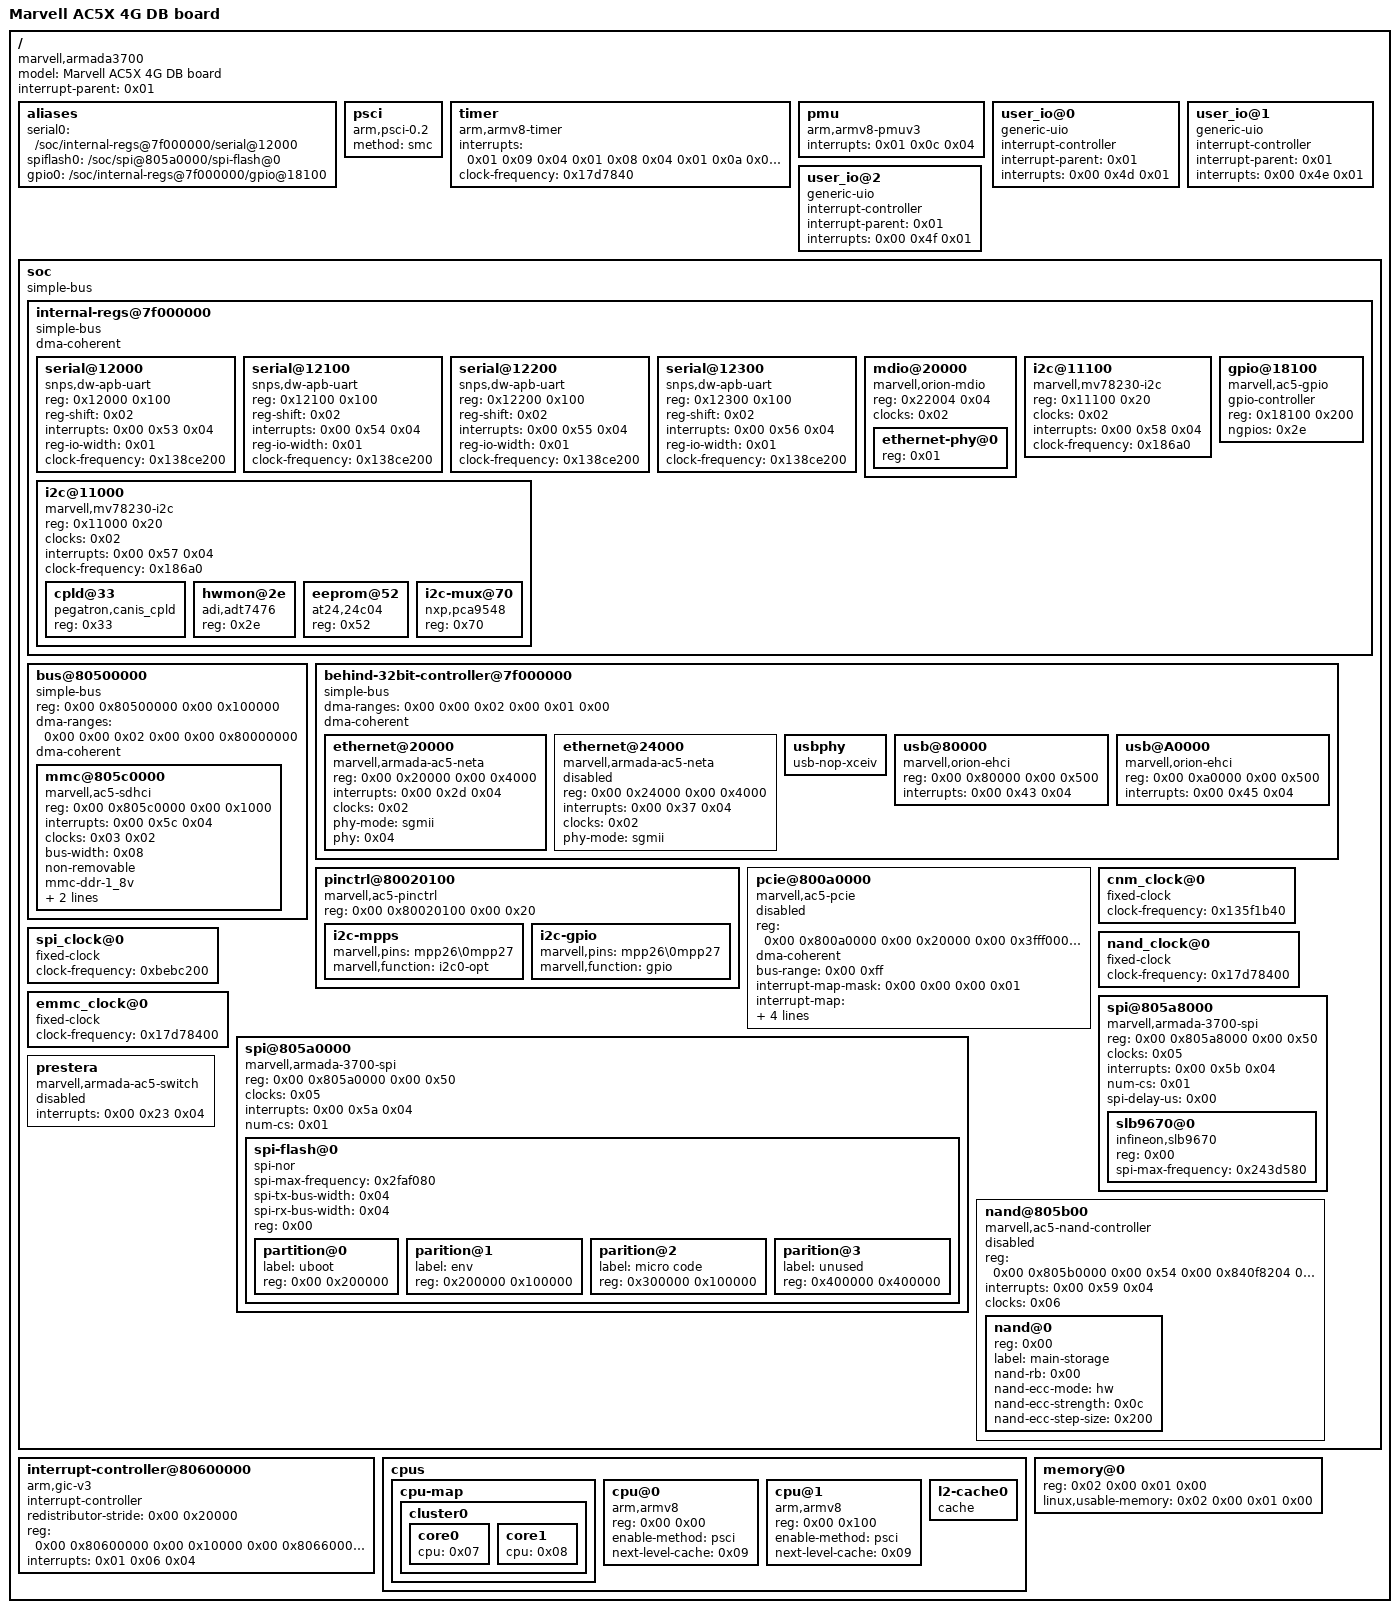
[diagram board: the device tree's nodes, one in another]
/dts-v1/;

/ {
	model = "Marvell AC5X 4G DB board";
	compatible = "marvell,armada3700";
	interrupt-parent = <0x01>;
	#address-cells = <0x02>;
	#size-cells = <0x02>;

	aliases {
		serial0 = "/soc/internal-regs@7f000000/serial@12000";
		spiflash0 = "/soc/spi@805a0000/spi-flash@0";
		gpio0 = "/soc/internal-regs@7f000000/gpio@18100";
	};

	psci {
		compatible = "arm,psci-0.2";
		method = "smc";
	};

	timer {
		compatible = "arm,armv8-timer";
		interrupts = <0x01 0x09 0x04 0x01 0x08 0x04 0x01 0x0a 0x04 0x01 0x07 0x04>;
		clock-frequency = <0x17d7840>;
	};

	pmu {
		compatible = "arm,armv8-pmuv3";
		interrupts = <0x01 0x0c 0x04>;
	};

	user_io@0 {
		compatible = "generic-uio";
		status = "okay";
		interrupt-controller;
		interrupt-parent = <0x01>;
		interrupts = <0x00 0x4d 0x01>;
	};

	user_io@1 {
		compatible = "generic-uio";
		status = "okay";
		interrupt-controller;
		interrupt-parent = <0x01>;
		interrupts = <0x00 0x4e 0x01>;
	};

	user_io@2 {
		compatible = "generic-uio";
		status = "okay";
		interrupt-controller;
		interrupt-parent = <0x01>;
		interrupts = <0x00 0x4f 0x01>;
	};

	soc {
		compatible = "simple-bus";
		#address-cells = <0x02>;
		#size-cells = <0x02>;
		ranges;

		internal-regs@7f000000 {
			#address-cells = <0x01>;
			#size-cells = <0x01>;
			compatible = "simple-bus";
			ranges = <0x00 0x00 0x7f000000 0x1000000>;
			dma-coherent;

			serial@12000 {
				compatible = "snps,dw-apb-uart";
				reg = <0x12000 0x100>;
				reg-shift = <0x02>;
				interrupts = <0x00 0x53 0x04>;
				reg-io-width = <0x01>;
				clock-frequency = <0x138ce200>;
				status = "okay";
			};

			serial@12100 {
				compatible = "snps,dw-apb-uart";
				reg = <0x12100 0x100>;
				reg-shift = <0x02>;
				interrupts = <0x00 0x54 0x04>;
				reg-io-width = <0x01>;
				clock-frequency = <0x138ce200>;
				status = "okay";
			};

			serial@12200 {
				compatible = "snps,dw-apb-uart";
				reg = <0x12200 0x100>;
				reg-shift = <0x02>;
				interrupts = <0x00 0x55 0x04>;
				reg-io-width = <0x01>;
				clock-frequency = <0x138ce200>;
				status = "okay";
			};

			serial@12300 {
				compatible = "snps,dw-apb-uart";
				reg = <0x12300 0x100>;
				reg-shift = <0x02>;
				interrupts = <0x00 0x56 0x04>;
				reg-io-width = <0x01>;
				clock-frequency = <0x138ce200>;
				status = "okay";
			};

			mdio@20000 {
				#address-cells = <0x01>;
				#size-cells = <0x00>;
				compatible = "marvell,orion-mdio";
				reg = <0x22004 0x04>;
				clocks = <0x02>;
				status = "okay";

				ethernet-phy@0 {
					reg = <0x01>;
					phandle = <0x04>;
				};
			};

			i2c@11000 {
				compatible = "marvell,mv78230-i2c";
				reg = <0x11000 0x20>;
				clocks = <0x02>;
				clock-names = "core";
				interrupts = <0x00 0x57 0x04>;
				clock-frequency = <0x186a0>;
				status = "okay";
				#address-cells = <0x01>;
				#size-cells = <0x00>;

				cpld@33 {
					compatible = "pegatron,canis_cpld";
					reg = <0x33>;
				};

				hwmon@2e {
					compatible = "adi,adt7476";
					reg = <0x2e>;
				};

				eeprom@52 {
					compatible = "at24,24c04";
					reg = <0x52>;
				};

				i2c-mux@70 {
					compatible = "nxp,pca9548";
					#address-cells = <0x01>;
					#size-cells = <0x00>;
					reg = <0x70>;
				};
			};

			i2c@11100 {
				compatible = "marvell,mv78230-i2c";
				reg = <0x11100 0x20>;
				clocks = <0x02>;
				clock-names = "core";
				interrupts = <0x00 0x58 0x04>;
				clock-frequency = <0x186a0>;
				status = "okay";
				#address-cells = <0x01>;
				#size-cells = <0x00>;
			};

			gpio@18100 {
				compatible = "marvell,ac5-gpio";
				#gpio-cells = <0x02>;
				gpio-controller;
				reg = <0x18100 0x200>;
				ngpios = <0x2e>;
				status = "okay";
			};
		};

		bus@80500000 {
			compatible = "simple-bus";
			ranges;
			#address-cells = <0x02>;
			#size-cells = <0x02>;
			reg = <0x00 0x80500000 0x00 0x100000>;
			dma-ranges = <0x00 0x00 0x02 0x00 0x00 0x80000000>;
			dma-coherent;

			mmc@805c0000 {
				compatible = "marvell,ac5-sdhci\0marvell,armada-ap806-sdhci";
				reg = <0x00 0x805c0000 0x00 0x1000>;
				interrupts = <0x00 0x5c 0x04>;
				clocks = <0x03 0x02>;
				clock-names = "core\0axi";
				bus-width = <0x08>;
				non-removable;
				mmc-ddr-1_8v;
				mmc-hs200-1_8v;
				mmc-hs400-1_8v;
			};
		};

		behind-32bit-controller@7f000000 {
			compatible = "simple-bus";
			#address-cells = <0x02>;
			#size-cells = <0x02>;
			ranges = <0x00 0x00 0x00 0x7f000000 0x00 0x1000000>;
			dma-ranges = <0x00 0x00 0x02 0x00 0x01 0x00>;
			dma-coherent;

			ethernet@20000 {
				compatible = "marvell,armada-ac5-neta";
				reg = <0x00 0x20000 0x00 0x4000>;
				interrupts = <0x00 0x2d 0x04>;
				clocks = <0x02>;
				status = "okay";
				phy-mode = "sgmii";
				phy = <0x04>;
			};

			ethernet@24000 {
				compatible = "marvell,armada-ac5-neta";
				reg = <0x00 0x24000 0x00 0x4000>;
				interrupts = <0x00 0x37 0x04>;
				clocks = <0x02>;
				status = "disabled";
				phy-mode = "sgmii";
			};

			usbphy {
				compatible = "usb-nop-xceiv";
				#phy-cells = <0x00>;
			};

			usb@80000 {
				compatible = "marvell,orion-ehci";
				reg = <0x00 0x80000 0x00 0x500>;
				interrupts = <0x00 0x43 0x04>;
				status = "okay";
			};

			usb@A0000 {
				reg = <0x00 0xa0000 0x00 0x500>;
				interrupts = <0x00 0x45 0x04>;
				status = "okay";
				compatible = "marvell,orion-ehci";
			};
		};

		pinctrl@80020100 {
			compatible = "marvell,ac5-pinctrl\0syscon\0simple-mfd";
			reg = <0x00 0x80020100 0x00 0x20>;

			i2c-mpps {
				marvell,pins = "mpp26\0mpp27";
				marvell,function = "i2c0-opt";
			};

			i2c-gpio {
				marvell,pins = "mpp26\0mpp27";
				marvell,function = "gpio";
			};
		};

		pcie@800a0000 {
			compatible = "marvell,ac5-pcie\0snps,dw-pcie";
			reg = <0x00 0x800a0000 0x00 0x20000 0x00 0x3fff0000 0x00 0x10000>;
			reg-names = "ctrl\0config";
			#address-cells = <0x03>;
			#size-cells = <0x02>;
			#interrupt-cells = <0x01>;
			device_type = "pci";
			dma-coherent;
			bus-range = <0x00 0xff>;
			ranges = <0x82000000 0x00 0x30000000 0x00 0x30000000 0x00 0xfff0000>;
			interrupt-map-mask = <0x00 0x00 0x00 0x01>;
			interrupt-map = <0x00 0x00 0x00 0x01 0x01 0x00 0x63 0x04>;
			interrupts = <0x00 0x63 0x04>;
			num-lanes = <0x01>;
			status = "disabled";
			clocks = <0x02>;
		};

		cnm_clock@0 {
			compatible = "fixed-clock";
			#clock-cells = <0x00>;
			clock-frequency = <0x135f1b40>;
			phandle = <0x02>;
		};

		spi_clock@0 {
			compatible = "fixed-clock";
			#clock-cells = <0x00>;
			clock-frequency = <0xbebc200>;
			phandle = <0x05>;
		};

		nand_clock@0 {
			compatible = "fixed-clock";
			#clock-cells = <0x00>;
			clock-frequency = <0x17d78400>;
			phandle = <0x06>;
		};

		emmc_clock@0 {
			compatible = "fixed-clock";
			#clock-cells = <0x00>;
			clock-frequency = <0x17d78400>;
			phandle = <0x03>;
		};

		spi@805a0000 {
			compatible = "marvell,armada-3700-spi";
			reg = <0x00 0x805a0000 0x00 0x50>;
			#address-cells = <0x01>;
			#size-cells = <0x00>;
			clocks = <0x05>;
			interrupts = <0x00 0x5a 0x04>;
			num-cs = <0x01>;
			status = "okay";

			spi-flash@0 {
				compatible = "spi-nor";
				spi-max-frequency = <0x2faf080>;
				spi-tx-bus-width = <0x04>;
				spi-rx-bus-width = <0x04>;
				reg = <0x00>;
				#address-cells = <0x01>;
				#size-cells = <0x01>;

				partition@0 {
					label = "uboot";
					reg = <0x00 0x200000>;
				};

				parition@1 {
					label = "env";
					reg = <0x200000 0x100000>;
				};

				parition@2 {
					label = "micro code";
					reg = <0x300000 0x100000>;
				};

				parition@3 {
					label = "unused";
					reg = <0x400000 0x400000>;
				};
			};
		};

		spi@805a8000 {
			compatible = "marvell,armada-3700-spi";
			reg = <0x00 0x805a8000 0x00 0x50>;
			#address-cells = <0x01>;
			#size-cells = <0x00>;
			clocks = <0x05>;
			interrupts = <0x00 0x5b 0x04>;
			num-cs = <0x01>;
			status = "okay";
			spi-delay-us = <0x00>;

			slb9670@0 {
				compatible = "infineon,slb9670\0tis,tpm2-spi\0tcg,tpm_tis-spi";
				reg = <0x00>;
				spi-max-frequency = <0x243d580>;
				status = "okay";
			};
		};

		nand@805b00 {
			compatible = "marvell,ac5-nand-controller";
			reg = <0x00 0x805b0000 0x00 0x54 0x00 0x840f8204 0x00 0x04 0x00 0x80013010 0x00 0x20>;
			#address-cells = <0x01>;
			#size-cells = <0x00>;
			interrupts = <0x00 0x59 0x04>;
			clocks = <0x06>;
			status = "disabled";

			nand@0 {
				reg = <0x00>;
				label = "main-storage";
				nand-rb = <0x00>;
				nand-ecc-mode = "hw";
				nand-ecc-strength = <0x0c>;
				nand-ecc-step-size = <0x200>;
			};
		};

		prestera {
			compatible = "marvell,armada-ac5-switch";
			interrupts = <0x00 0x23 0x04>;
			status = "disabled";
		};
	};

	interrupt-controller@80600000 {
		compatible = "arm,gic-v3";
		#interrupt-cells = <0x03>;
		interrupt-controller;
		redistributor-stride = <0x00 0x20000>;
		reg = <0x00 0x80600000 0x00 0x10000 0x00 0x80660000 0x00 0x40000>;
		interrupts = <0x01 0x06 0x04>;
		phandle = <0x01>;
	};

	cpus {
		#address-cells = <0x02>;
		#size-cells = <0x00>;

		cpu-map {

			cluster0 {

				core0 {
					cpu = <0x07>;
				};

				core1 {
					cpu = <0x08>;
				};
			};
		};

		cpu@0 {
			device_type = "cpu";
			compatible = "arm,armv8";
			reg = <0x00 0x00>;
			enable-method = "psci";
			next-level-cache = <0x09>;
			phandle = <0x07>;
		};

		cpu@1 {
			device_type = "cpu";
			compatible = "arm,armv8";
			reg = <0x00 0x100>;
			enable-method = "psci";
			next-level-cache = <0x09>;
			phandle = <0x08>;
		};

		l2-cache0 {
			compatible = "cache";
			phandle = <0x09>;
		};
	};

	memory@0 {
		device_type = "memory";
		reg = <0x02 0x00 0x01 0x00>;
		linux,usable-memory = <0x02 0x00 0x01 0x00>;
	};
};
